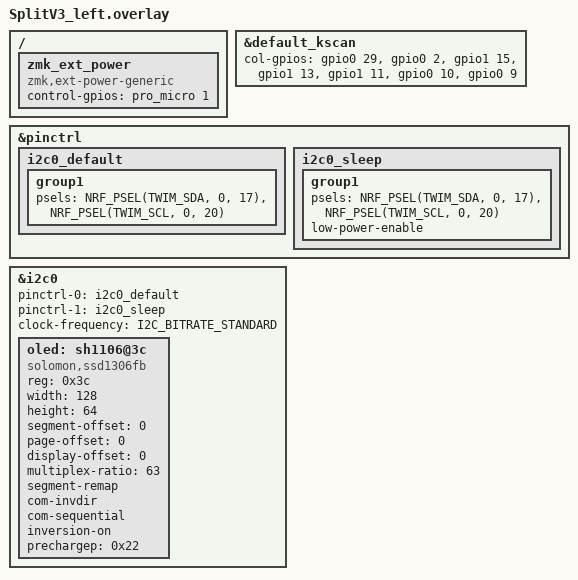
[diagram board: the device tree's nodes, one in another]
#include  "SplitV3.dtsi"

&default_kscan {
        col-gpios = <&gpio0 29 (GPIO_ACTIVE_HIGH)>,
                    <&gpio0 2 (GPIO_ACTIVE_HIGH)>,
                    <&gpio1 15 (GPIO_ACTIVE_HIGH)>,
                    <&gpio1 13 (GPIO_ACTIVE_HIGH)>,
                    <&gpio1 11 (GPIO_ACTIVE_HIGH)>,
                    <&gpio0 10 (GPIO_ACTIVE_HIGH)>,
                    <&gpio0 9  (GPIO_ACTIVE_HIGH)>;
    };

&pinctrl {
    i2c0_default: i2c0_default {
        group1 {
            psels = <NRF_PSEL(TWIM_SDA, 0, 17)>,
                <NRF_PSEL(TWIM_SCL, 0, 20)>;
        };
    };

    i2c0_sleep: i2c0_sleep {
        group1 {
            psels = <NRF_PSEL(TWIM_SDA, 0, 17)>,
                <NRF_PSEL(TWIM_SCL, 0, 20)>;
            low-power-enable;
        };
    };	
}; 

&i2c0 {
    status = "okay";
    pinctrl-0 = <&i2c0_default>;
    pinctrl-1 = <&i2c0_sleep>;
    pinctrl-names = "default", "sleep";
    clock-frequency = <I2C_BITRATE_STANDARD>;
};

/ {
    zmk_ext_power {
        compatible = "zmk,ext-power-generic";
        control-gpios = <&pro_micro 1 GPIO_ACTIVE_HIGH>; 
    };
};

&i2c0 {
	status = "okay";
    pinctrl-0 = <&i2c0_default>;
    pinctrl-1 = <&i2c0_sleep>;
	oled: sh1106@3c {
        compatible = "solomon,ssd1306fb";
        reg = <0x3c>;
        width = <128>;
        height = <64>;
        segment-offset = <0>;
        page-offset = <0>;
        display-offset = <0>;
        multiplex-ratio = <63>;
        segment-remap;
        com-invdir;
        com-sequential;
        inversion-on;
        prechargep = <0x22>;
	};
};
